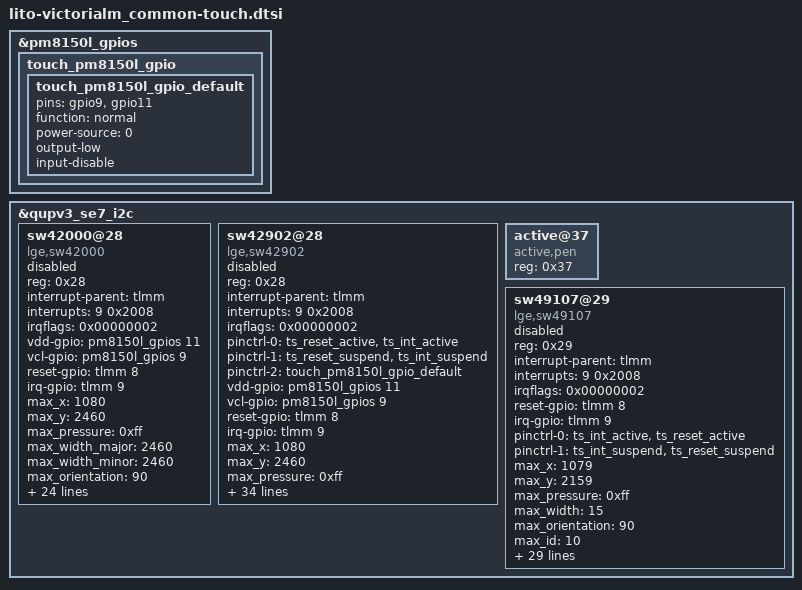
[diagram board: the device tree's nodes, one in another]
// SPDX-License-Identifier: GPL-2.0-only
/*
 * Copyright (c) 2018-2019, The Linux Foundation. All rights reserved.
 */

&pm8150l_gpios {
	touch_pm8150l_gpio{
		touch_pm8150l_gpio_default: touch_pm8150l_gpio_default {
			pins = "gpio9", "gpio11";
			function = "normal";
			power-source = <0>;
			output-low;
			input-disable;
		};
	};
};

&qupv3_se7_i2c {
	sw42000@28 {
		status = "disable";
		compatible = "lge,sw42000";

		reg = <0x28>;
		interrupt-parent = <&tlmm>;
		interrupts = <9 0x2008>;
		irqflags = <0x00000002>;

		vdd-gpio = <&pm8150l_gpios 11 0x00>;
		vcl-gpio = <&pm8150l_gpios 9 0x00>;
		reset-gpio = <&tlmm 8 0x00>;
		irq-gpio = <&tlmm 9 0x2008>;

		/* caps */
		max_x = <1080>;
		max_y = <2460>;
		max_pressure = <0xff>;
		max_width_major = <2460>;
		max_width_minor = <2460>;
		max_orientation = <90>;
		max_id = <10>;
		hw_reset_delay = <90>;
		sw_reset_delay = <10>;

		/* Role */
		use_lpwg = <1>;
		use_lpwg_test = <1>;
		hide_coordinate = <0>;
		use_film_status = <1>;

		/* Firmware */
		fw_image = "touch/caymanlm/B0W68TIME_0_02.img";
		panel_spec = "touch/caymanlm/caymanlm_sw42000_limit.txt";
		panel_spec_mfts_folder = "touch/caymanlm/caymanlm_sw42000_limit.txt";

		/* Performance Test */
		use_perf_test = <1>;
		test_delay = <8>;
		test_pressure = <50>;
		test_width = <100>;
		click_test_x = <180>;
		click_test_y = <838>;
		v_drag_test_x = <144>;
		v_drag_test_start_y = <2103>;
		v_drag_test_end_y = <1216>;
		h_drag_test_start_x = <1163>;
		h_drag_test_end_x = <276>;
		h_drag_test_y = <2284>;
	};
	sw42902@28 {
		compatible = "lge,sw42902";
		reg = <0x28>;
		status = "disabled";
		interrupt-parent = <&tlmm>;
		interrupts = <9 0x2008>;
		irqflags = <0x00000002>;

		pinctrl-names = "touch_pin_active", "touch_pin_sleep", "touch_pm8150l_gpio_default";
		pinctrl-0 = <&ts_reset_active &ts_int_active>;
		pinctrl-1 = <&ts_reset_suspend &ts_int_suspend>;
		pinctrl-2 = <&touch_pm8150l_gpio_default>;

		vdd-gpio = <&pm8150l_gpios 11 0x00>;
		vcl-gpio = <&pm8150l_gpios 9 0x00>;
		reset-gpio = <&tlmm 8 0x00>;
		irq-gpio = <&tlmm 9 0x2008>;

		/* caps */
		max_x = <1080>;
		max_y = <2460>;
		max_pressure = <0xff>;
		max_width_major = <2460>;
		max_width_minor = <2460>;
		max_orientation = <90>;
		max_id = <10>;
		hw_reset_delay = <90>;
		sw_reset_delay = <10>;

		/* role */
		use_lpwg = <1>;
		use_lpwg_test = <1>;
		hide_coordinate = <1>;
		use_activepen_status = <1>;
		use_film_status = <1>;
		use_dex_mode = <1>;

		/* firmware */
		fw_image = "touch/caymanlm/B3W68CAYMAN_0_18.img",
			   "touch/caymanlm/B3W68DS3_0_24.img";

		panel_spec = "touch/caymanlm/cayman_sw42902_limit.txt";
		panel_spec_mfts_folder = "touch/caymanlm/cayman_sw42902_limit.txt";

		/* asc */
		use_asc = <0>;
		low_delta_thres = <350>;
		high_delta_thres = <600>;
		max_delta_cnt = <2>;

		/* Performance Test */
		use_perf_test = <1>;
		test_delay = <8>;
		test_pressure = <50>;
		test_width = <100>;
		click_test_x = <180>;
		click_test_y = <760>;
		v_drag_test_x = <144>;
		v_drag_test_start_y = <2003>;
		v_drag_test_end_y = <1116>;
		h_drag_test_start_x = <1163>;
		h_drag_test_end_x = <276>;
		h_drag_test_y = <2184>;
	};

	/* Temp Slave Address */
	active@37 {
		compatible = "active,pen";
		status = "ok";
		reg = <0x37>;
	};

	sw49107@29 {
		compatible = "lge,sw49107";
		status = "disable";

		reg = <0x29>;
		interrupt-parent = <&tlmm>;
		/* IRQF_ONESHOT			0x00002000 */
		/* IRQF_TRIGGER_FALLING		0x00000002 */
		/* IRQF_NO_SUSPEND		0x00004000 */
		interrupts = <9 0x2008>;
		irqflags = <0x00000002>;
		
		reset-gpio = <&tlmm 8 0x00>;
		irq-gpio = <&tlmm 9 0x2002>;

		pinctrl-names = "touch_pin_active","touch_pin_sleep";	/*Touch GPIO pin name setting*/
		pinctrl-0 = <&ts_int_active &ts_reset_active>;		/*Touch GPIO pin active setting*/
		pinctrl-1 = <&ts_int_suspend &ts_reset_suspend>;	/*Touch GPIO pin suspend setting*/

		/* Caps */
		max_x = <1079>;
		max_y = <2159>;
		max_pressure = <0xff>;
		max_width = <15>;
		max_orientation = <90>;
		max_id = <10>;
		hw_reset_delay = <210>;
		sw_reset_delay = <90>;

		/* Role */
		use_lpwg = <1>;
		use_lpwg_test = <1>;
		hide_coordinate = <0>;

		/* firmware */
		use_fw_upgrade = <1>;
		use_firmware = <0>;
		fw_image = "touch/cv7as/lgsic/L1W62CV7AS_V1_01.img", "touch/caymanlm/T1W62CAYMAN_V1_02.img";
		panel_spec = "touch/caymanlm/caymanlm_lcd_limit.txt", "touch/caymanlm/caymanlm_lcd_limit.txt";
		panel_spec_mfts_folder = "touch/caymanlm/caymanlm_lcd_limit.txt", "touch/caymanlm/caymanlm_lcd_limit.txt";

		/* Performance Test */
		test_jig_size = <6>;
		use_perf_test = <1>;
		test_delay = <8>;
		test_pressure = <50>;
		test_width = <100>;
		click_test_x = <135>;
		click_test_y = <526>;
		v_drag_test_x = <108>;
		v_drag_test_start_y = <1388>;
		v_drag_test_end_y = <771>;
		h_drag_test_start_x = <848>;
		h_drag_test_end_x = <231>;
		h_drag_test_y = <1512>;
	};
};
